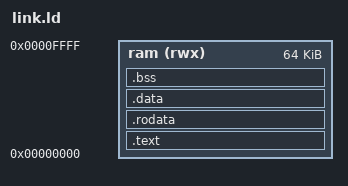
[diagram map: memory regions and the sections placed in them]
ENTRY(_start)
MEMORY { ram (rwx) : ORIGIN = 0, LENGTH = 64K }
SECTIONS {
    .text : { KEEP(*(.text.start)) *(.text*) } > ram
    .rodata : { *(.rodata*) } > ram
    .data : { *(.data*) *(.sdata*) } > ram
    .bss (NOLOAD) : {
        . = ALIGN(4); _bss_start = .;
        *(.bss*) *(.sbss*) *(COMMON)
        . = ALIGN(4); _bss_end = .;
    } > ram
    ASSERT(_bss_end < 0xf000, "Firmware overlaps reserved 4 KiB stack")
}
